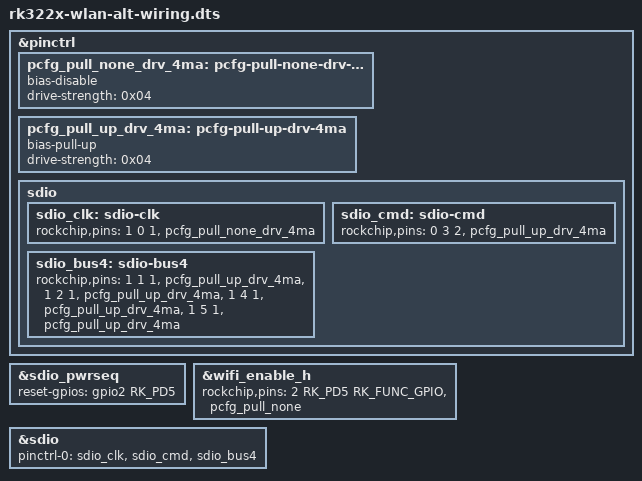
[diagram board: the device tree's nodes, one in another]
/dts-v1/;
/plugin/;

#include <dt-bindings/gpio/gpio.h>
#include <dt-bindings/pinctrl/rockchip.h>

/ {

	fragment@0 {
		target = <&pinctrl>;
		__overlay__ {

			pcfg_pull_none_drv_4ma: pcfg-pull-none-drv-4ma {
				bias-disable;
				drive-strength = <0x04>;
			};

			pcfg_pull_up_drv_4ma: pcfg-pull-up-drv-4ma {
				bias-pull-up;
				drive-strength = <0x04>;
			};

			sdio {
				sdio_clk: sdio-clk {
					rockchip,pins = <1 0 1 &pcfg_pull_none_drv_4ma>;
				};

				sdio_cmd: sdio-cmd {
					rockchip,pins = <0 3 2 &pcfg_pull_up_drv_4ma>;
				};

				sdio_bus4: sdio-bus4 {
					rockchip,pins = <1 1 1 &pcfg_pull_up_drv_4ma>,
							<1 2 1 &pcfg_pull_up_drv_4ma>,
							<1 4 1 &pcfg_pull_up_drv_4ma>,
							<1 5 1 &pcfg_pull_up_drv_4ma>;
				};
			};

		};

	};

	fragment@1 {
		target = <&sdio_pwrseq>;
		__overlay__ {
			reset-gpios = <&gpio2 RK_PD5 GPIO_ACTIVE_HIGH>;
		};
	};

	fragment@2 {
		target = <&wifi_enable_h>;
		__overlay__ {
			rockchip,pins = <2 RK_PD5 RK_FUNC_GPIO &pcfg_pull_none>;
		};
	};

	fragment@3 {
		target = <&sdio>;
		__overlay__ {
			pinctrl-names = "default";
			pinctrl-0 = <&sdio_clk &sdio_cmd &sdio_bus4>;
		};

	};

};
